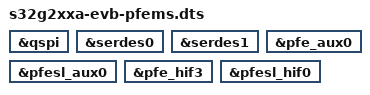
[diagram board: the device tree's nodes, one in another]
// SPDX-License-Identifier: GPL-2.0-or-later
/*
 * Device Tree file for S32G-PROCEVB with S32G2 + S32GRV-VNP-PLAT boards
 * PFE Master/Slave mode supported
 *
 * Copyright 2022-2024 NXP
 */

#include "s32g2xxa-evb.dtsi"
#include "s32g-pfe-slave.dtsi"

&qspi {
	status = "okay";
};

&serdes0 {
	status = "okay";
};

&serdes1 {
	status = "okay";
};

&pfe_aux0 {
	status = "okay";
};

&pfesl_aux0 {
	status = "okay";
};

&pfe_hif3 {
	status = "okay";
};

&pfesl_hif0 {
	status = "okay";
};
